VERSION "HIPBNYYYYYYYYYYYYYYYYYYYYYYYYYYYYYYYYYYYYY/4/%%%/4/'%**4YYY///"

NS_ :

BS_:

BU_:

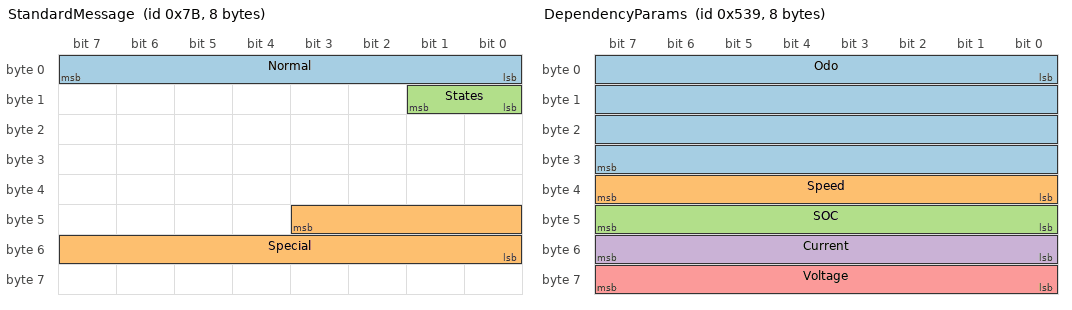
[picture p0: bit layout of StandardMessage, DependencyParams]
BO_ 123 StandardMessage: 8 Vector__XXX
 SG_ Normal : 0|8@1+ (1,0) [0|255] "A" Vector__XXX
 SG_ Special : 43|12@0- (0.5,-50) [0|300] "V" Example_category
 SG_ States : 8|2@1+ (1,0) [0|20] "" Vector__XXX

BO_ 2566906689 ExtendedMessage: 8 Vector__XXX
 SG_ Multiplexor M : 0|8@1+ (1,0) [0|10] "" Vector__XXX
 SG_ BatteryCell1Voltage m0 : 8|16@1+ (1,0) [0|11] "V" Vector__XXX
 SG_ BatteryCell2Voltage m1 : 8|16@1+ (1,0) [0|12] "V" Vector__XXX

BO_ 1337 DependencyParams: 8 Important
 SG_ Odo : 0|32@1+ (0.05,0) [0|100000] "km" Vector__XXX
 SG_ Speed : 32|8@1+ (1,0) [0|150] "km/h" Vector__XXX
 SG_ SOC : 40|8@1+ (0.5,0) [0|100] "%" Vector__XXX
 SG_ Current : 48|8@1+ (4,0) [0|1000] "A" Vector__XXX
 SG_ Voltage : 56|8@1+ (4,0) [0|1000] "V" Vector__XXX

VAL_ 123 States 0 "Off" 1 "On" 2 "Blinking" 3 "Unavailable" ;

CM_ BO_ 1337 "Small description on BO";
CM_ SG_ 1337 Speed "Small description on SG";
CM_ BU_ 1337 "Small description on BU";
